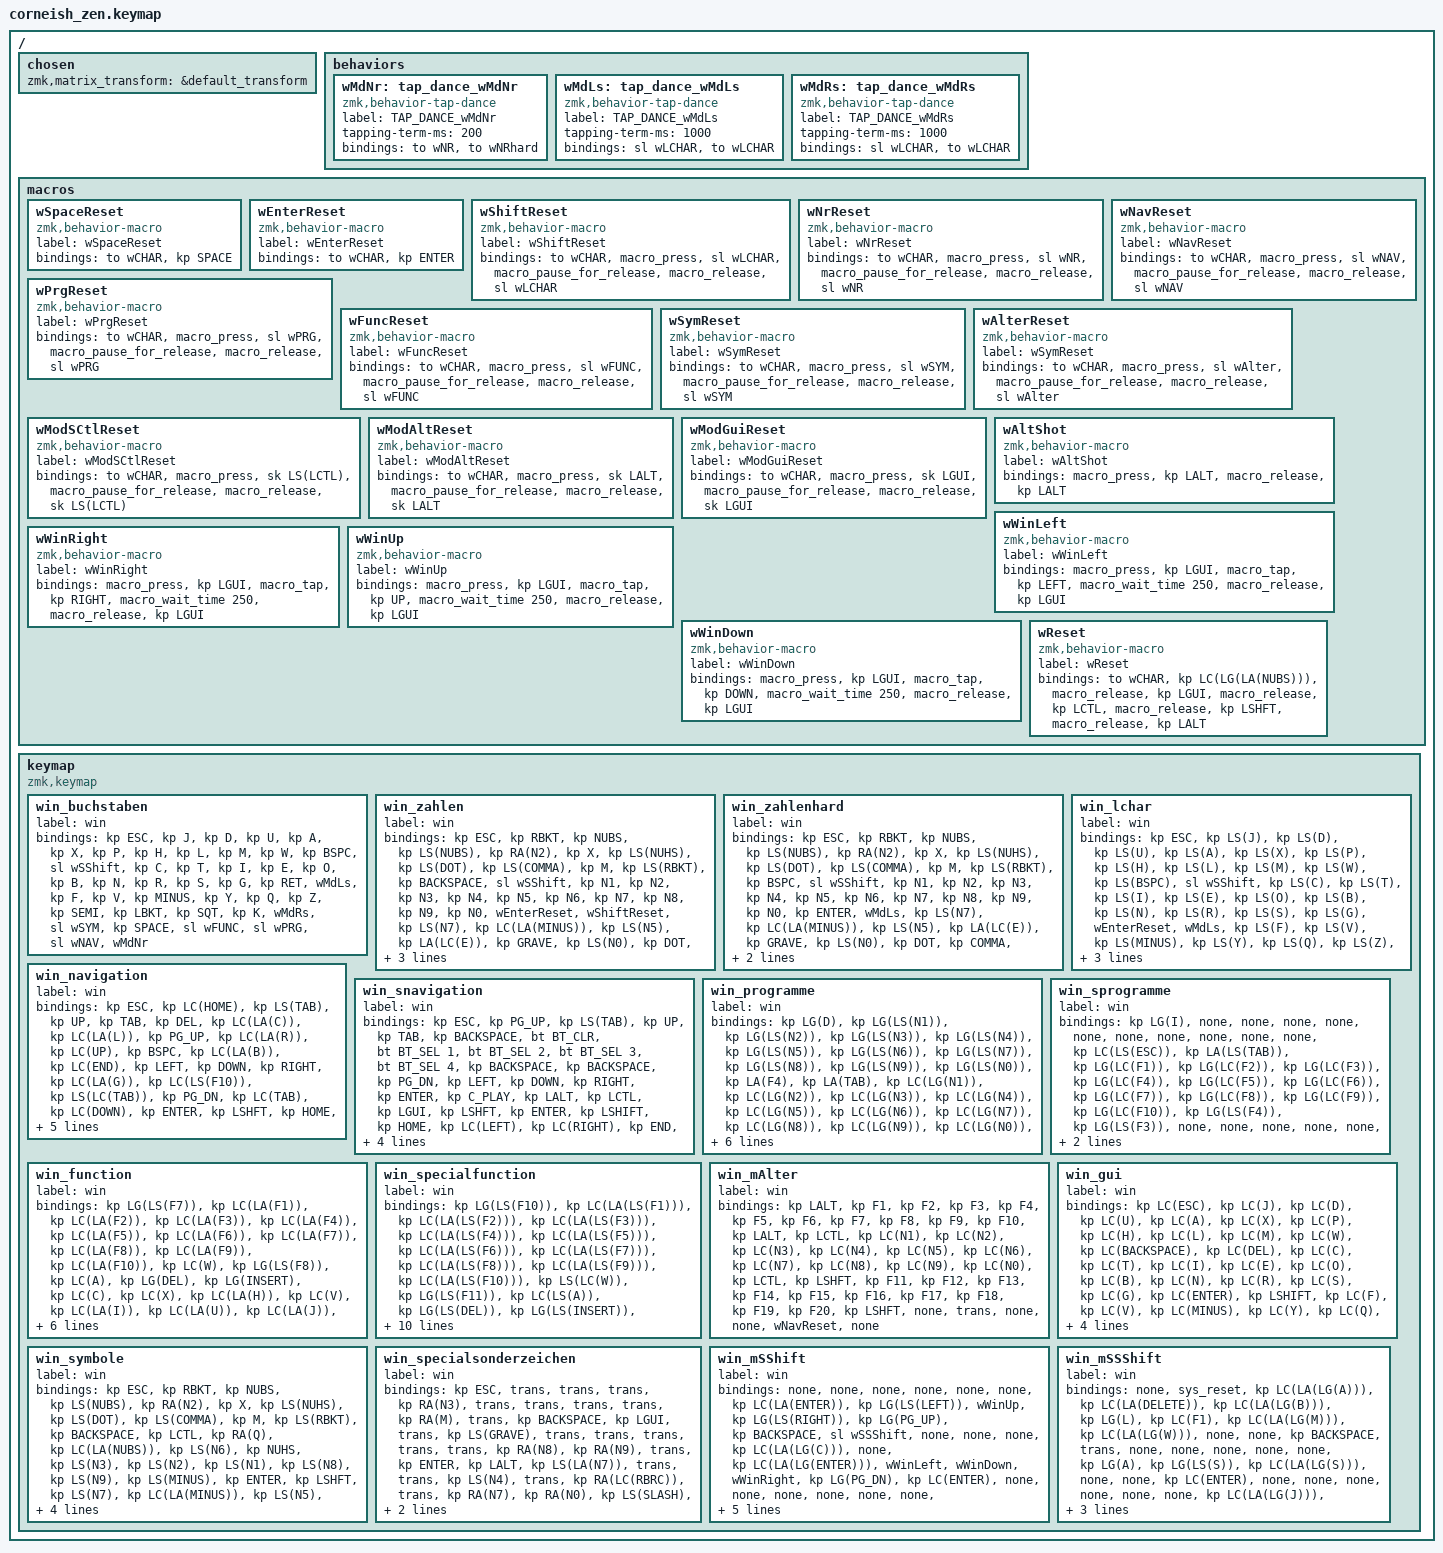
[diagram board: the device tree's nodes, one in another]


#include <behaviors.dtsi>
#include <dt-bindings/zmk/keys.h>
#include <dt-bindings/zmk/bt.h>





// ------- WIN -------------------


#define wCHAR 0
#define wNR 1
#define wNRhard 2
#define wLCHAR 3

#define wNAV 4
#define wSNAV 5

#define wPRG 6
#define wSPRG 7

#define wFUNC 8
#define wSFUNC 9
#define wAlter 10
#define wGUI 11

#define wSYM 12
#define wSSYM 13

#define wSShift 14
#define wSSShift 15



/ {
    chosen {
    	zmk,matrix_transform = &default_transform;
    };
};




/ {

    behaviors 
	{

		// Tap Dance Number
		wMdNr: tap_dance_wMdNr 
		{
            compatible = "zmk,behavior-tap-dance";
            label = "TAP_DANCE_wMdNr";
            #binding-cells = <0>;
            tapping-term-ms = <200>;
            bindings = <&to wNR>, <&to wNRhard>;
        };

		//Tab Dance Shift
		wMdLs: tap_dance_wMdLs 
		{
            compatible = "zmk,behavior-tap-dance";
            label = "TAP_DANCE_wMdLs";
            #binding-cells = <0>;
            tapping-term-ms = <1000>;
            bindings = <&sl wLCHAR>, <&to wLCHAR>;
        };
		wMdRs: tap_dance_wMdRs 
		{
            compatible = "zmk,behavior-tap-dance";
            label = "TAP_DANCE_wMdRs";
            #binding-cells = <0>;
            tapping-term-ms = <1000>;
            bindings = <&sl wLCHAR>, <&to wLCHAR>;
        };

    };

	
	macros 
	{

		//Reset Keys
        wSpaceReset: wSpaceReset 
		{
            label = "wSpaceReset";
            compatible = "zmk,behavior-macro";
            #binding-cells = <0>;
            bindings
                = <&to wCHAR>
                , <&kp SPACE>
                ;
    	};
		wEnterReset: wEnterReset 
		{
            label = "wEnterReset";
            compatible = "zmk,behavior-macro";
            #binding-cells = <0>;
            bindings
                = <&to wCHAR>
                , <&kp ENTER>
                ;
    	};
		wShiftReset: wShiftReset
		{
            label = "wShiftReset";
            compatible = "zmk,behavior-macro";
            #binding-cells = <0>;
            bindings
                = <&to wCHAR>
                , <&macro_press &sl wLCHAR>
    			, <&macro_pause_for_release>
				, <&macro_release &sl wLCHAR>
                ;
    	};



		//Reset Daumen

		wNrReset: wNrReset
		{
            label = "wNrReset";
            compatible = "zmk,behavior-macro";
            #binding-cells = <0>;
            bindings
                = <&to wCHAR>
                , <&macro_press &sl wNR>
    			, <&macro_pause_for_release>
				, <&macro_release &sl wNR>
				;
    	};

				
		wNavReset: wNavReset 
		{
            label = "wNavReset";
            compatible = "zmk,behavior-macro";
            #binding-cells = <0>;
            bindings
                = <&to wCHAR>
                , <&macro_press &sl wNAV>
    			, <&macro_pause_for_release>
				, <&macro_release &sl wNAV>
                ;
    	};

		wPrgReset: wPrgReset 
		{
            label = "wPrgReset";
            compatible = "zmk,behavior-macro";
            #binding-cells = <0>;
            bindings
                = <&to wCHAR>
                , <&macro_press &sl wPRG>
    			, <&macro_pause_for_release>
				, <&macro_release &sl wPRG>
                ;
    	};

		wFuncReset: wFuncReset
		{
            label = "wFuncReset";
            compatible = "zmk,behavior-macro";
            #binding-cells = <0>;
            bindings
                = <&to wCHAR>
                , <&macro_press &sl wFUNC>
    			, <&macro_pause_for_release>
				, <&macro_release &sl wFUNC>
                ;
    	};

		wSymReset: wSymReset
		{
            label = "wSymReset";
            compatible = "zmk,behavior-macro";
            #binding-cells = <0>;
            bindings
                = <&to wCHAR>
                , <&macro_press &sl wSYM>
    			, <&macro_pause_for_release>
				, <&macro_release &sl wSYM>
                ;
    	};



		wAlterReset: wAlterReset
		{
            label = "wSymReset";
            compatible = "zmk,behavior-macro";
            #binding-cells = <0>;
            bindings
                = <&to wCHAR>
                , <&macro_press &sl wAlter>
    			, <&macro_pause_for_release>
				, <&macro_release &sl wAlter>
                ;
    	};


		wModSCtlReset: wModSCtlReset
		{
            label = "wModSCtlReset";
            compatible = "zmk,behavior-macro";
            #binding-cells = <0>;
            bindings
                = <&to wCHAR>
                , <&macro_press &sk LS(LCTL)>
    			, <&macro_pause_for_release>
				, <&macro_release &sk LS(LCTL)>
                ;
    	};


		wModAltReset: wModAltReset
		{
            label = "wModAltReset";
            compatible = "zmk,behavior-macro";
            #binding-cells = <0>;
            bindings
                = <&to wCHAR>
                , <&macro_press &sk LALT>
    			, <&macro_pause_for_release>
				, <&macro_release &sk LALT>
                ;
    	};

		wModGuiReset: wModGuiReset 
		{
            label = "wModGuiReset";
            compatible = "zmk,behavior-macro";
            #binding-cells = <0>;
            bindings
                = <&to wCHAR>
                , <&macro_press &sk LGUI>
    			, <&macro_pause_for_release>
				, <&macro_release &sk LGUI>
                ;
    	};


		// specials

		wAltShot: wAltShot {
            label = "wAltShot";
            compatible = "zmk,behavior-macro";
            #binding-cells = <0>;
            bindings
                = <&macro_press &kp LALT>
				, <&macro_release  &kp LALT>
                ;
    	};


		// Window

		wWinLeft: wWinLeft {
            label = "wWinLeft";
            compatible = "zmk,behavior-macro";
            #binding-cells = <0>;
            bindings
                = <&macro_press &kp LGUI>
				, <&macro_tap &kp LEFT>
				, <&macro_wait_time 250>
				, <&macro_release  &kp LGUI>
                ; 
    	};

		wWinRight: wWinRight {
            label = "wWinRight";
            compatible = "zmk,behavior-macro";
            #binding-cells = <0>;
            bindings
                = <&macro_press &kp LGUI>
				, <&macro_tap &kp RIGHT>
				, <&macro_wait_time 250>
				, <&macro_release  &kp LGUI>
                ; 
    	};

		wWinUp: wWinUp {
            label = "wWinUp";
            compatible = "zmk,behavior-macro";
            #binding-cells = <0>;
            bindings
                = <&macro_press &kp LGUI>
				, <&macro_tap &kp UP>
				, <&macro_wait_time 250>
				, <&macro_release  &kp LGUI>
                ; 
    	};

		wWinDown: wWinDown {
            label = "wWinDown";
            compatible = "zmk,behavior-macro";
            #binding-cells = <0>;
            bindings
                = <&macro_press &kp LGUI>
				, <&macro_tap &kp DOWN>
				, <&macro_wait_time 250>
				, <&macro_release  &kp LGUI>
                ; 
    	};


		// Reset

		wReset: wReset {
            label = "wReset";
            compatible = "zmk,behavior-macro";
            #binding-cells = <0>;
            bindings
				= <&to wCHAR>
				, <&kp LC(LG(LA(NUBS)))>
				, <&macro_release  &kp LGUI>
				, <&macro_release  &kp LCTL>
				, <&macro_release  &kp LSHFT>
				, <&macro_release  &kp LALT>
                ; 
    	};

	};





	keymap
	{	
		compatible = "zmk,keymap";



		// -----------------------------------------------------|
		// Layer 0 - mChar = 	  Buchstaben					|
		// -----------------------------------------------------|
	
		win_buchstaben
		{
			label = "win";

			bindings = <

				// ----------------------------------------

				&kp ESC
				&kp J 
				&kp D	 
				&kp U
				&kp A
				&kp X

				&kp P
				&kp H
				&kp L
				&kp M
				&kp W
				&kp BSPC

				// ----------------------------------------
	
				&sl wSShift
				&kp C
				&kp T
				&kp I
				&kp E
				&kp O

				&kp B
				&kp N
				&kp R
				&kp S
				&kp G
				&kp RET

				// ----------------------------------------
	
				&wMdLs
				&kp F
				&kp V
				&kp MINUS
				&kp Y
				&kp Q

				&kp Z
				&kp SEMI
				&kp LBKT
				&kp SQT
				&kp K
				&wMdRs

				// ----------------------------------------

				&sl wSYM
				&kp SPACE
				&sl wFUNC
				&sl wPRG 
				&sl wNAV
				&wMdNr

				// ----------------------------------------
			>;
		};



		// -----------------------------------------------------|
		// Layer 1 - mNR = 	  Zahlen 							|
		// -----------------------------------------------------|

		win_zahlen
		{
			label = "win";

			bindings = <

				// ----------------------------------------

				&kp ESC	
				&kp RBKT  				// +
				&kp NUBS				// Spitze
				&kp LS(NUBS)			// Spitze
				&kp RA(N2)				// hoch 2
				&kp X
				
				&kp LS(NUHS)			// '
				&kp LS(DOT)				// :
				&kp LS(COMMA)			// ;
				&kp M
				&kp LS(RBKT)			// *				
				&kp BACKSPACE

				// ----------------------------------------

				&sl wSShift
				&kp N1				
				&kp N2				
				&kp N3				
				&kp N4					
				&kp N5		

				&kp N6				
				&kp N7				
				&kp N8			
				&kp N9				
				&kp N0				
				&wEnterReset 

				// ----------------------------------------

				&wShiftReset
				&kp LS(N7)				// /
				&kp LC(LA(MINUS))		// backlslash
				&kp LS(N5)				// %
				&kp LA(LC(E))			// €
				&kp GRAVE				// ^

				&kp LS(N0)				// =
				&kp DOT					// .
				&kp COMMA				// ,
				&kp LS(SLASH)			// _
				&kp SLASH 				// -
				&wShiftReset

				// ----------------------------------------
		
				&wSymReset
				&wSpaceReset 
				&wFuncReset
				&wPrgReset
				&wNavReset
				&none
			>;		
		};



		// -----------------------------------------------------|
		// 2 Layer  - wNRhard = 	  Zahlen Hard Lock				|
		// -----------------------------------------------------|

		win_zahlenhard
		{
			label = "win";

			bindings = <

				// ----------------------------------------

				&kp ESC	
				&kp RBKT  				// +
				&kp NUBS				// Spitze
				&kp LS(NUBS)			// Spitze
				&kp RA(N2)				// hoch 2
				&kp X
				
				&kp LS(NUHS)			// '
				&kp LS(DOT)				// :
				&kp LS(COMMA)			// ;
				&kp M
				&kp LS(RBKT)			// *	
				&kp BSPC

				// ----------------------------------------

				&sl wSShift
				&kp N1				
				&kp N2				
				&kp N3				
				&kp N4					
				&kp N5		

				&kp N6				
				&kp N7				
				&kp N8				
				&kp N9				
				&kp N0				
				&kp ENTER 

				// ----------------------------------------

				&wMdLs
				&kp LS(N7)				// /
				&kp LC(LA(MINUS))		// backlslash
				&kp LS(N5)				// %
				&kp LA(LC(E))			// €
				&kp GRAVE				// ^

				&kp LS(N0)				// =
				&kp DOT					// .
				&kp COMMA				// ,
				&kp LS(SLASH)			// _
				&kp SLASH 				// -
				&wMdRs

				// ----------------------------------------
		
				&sl wSYM
				&kp SPACE
				&sl wFUNC
				&sl wPRG 
				&wNavReset
				&none
			>;		
		};




		// -----------------------------------------------------|
		// 3 Layer  - mLCHAR = 	  Buchstaben Lock				|
		// -----------------------------------------------------|
	
		win_lchar
		{
			label = "win";

			bindings = <

				// ----------------------------------------

				&kp ESC
				&kp LS(J) 
				&kp LS(D)	 
				&kp LS(U)
				&kp LS(A)
				&kp LS(X)

				&kp LS(P)
				&kp LS(H)
				&kp LS(L)
				&kp LS(M)
				&kp LS(W)
				&kp LS(BSPC)

				// ----------------------------------------
	
				&sl wSShift
				&kp LS(C)
				&kp LS(T)
				&kp LS(I)
				&kp LS(E)
				&kp LS(O)
			
				&kp LS(B)
				&kp LS(N)
				&kp LS(R)
				&kp LS(S)
				&kp LS(G)
				&wEnterReset

				// ----------------------------------------

				&wMdLs
				&kp LS(F)
				&kp LS(V)
				&kp LS(MINUS)
				&kp LS(Y)
				&kp LS(Q)

				&kp LS(Z)
				&kp LS(SEMI)
				&kp LS(LBKT)
				&kp LS(SQT)
				&kp LS(K)
				&wMdRs					

				// ----------------------------------------

				&wSymReset
				&wSpaceReset 
				&wFuncReset
				&wPrgReset
				&sl wNAV
				&wMdNr

				// ----------------------------------------		
			>;
		};




		// -----------------------------------------------------|
		// Layer = 4 - wNAV - Navigation						|
		// -----------------------------------------------------|

		win_navigation
		{		
			label = "win";

			bindings = <

				// ----------------------------------------

				&kp ESC
				&kp LC(HOME)				// @Home Sprung
				&kp LS(TAB)
				&kp UP						// @Up
				&kp TAB
				&kp DEL

				&kp LC(LA(C))	
				&kp LC(LA(L))			
				&kp PG_UP
				&kp LC(LA(R))		 	 
				&kp LC(UP)
				&kp BSPC					

				// ----------------------------------------

				&kp LC(LA(B))	
				&kp LC(END)					// @End Sprung
				&kp LEFT 					// @Left
				&kp DOWN					// @Down
				&kp RIGHT 					// @Right
				&kp LC(LA(G))	

				&kp LC(LS(F10))
				&kp LS(LC(TAB))			 	// 
				&kp PG_DN
				&kp LC(TAB)				 	// 
				&kp LC(DOWN)
				&kp ENTER					// -
				
				// ----------------------------------------

				&kp LSHFT
				&kp HOME					// @Home 
				&kp LC(LEFT)				// @Wort Sprung
				&kp LC(RIGHT)				// @Wort Sprung
				&kp END
				&kp LC(LA(LS(C)))	

				&wAltShot
				&kp LS(HOME)					// @Home 
				&kp LS(LC(LEFT))				// @Wort Sprung
				&kp LS(LC(RIGHT))				// @Wort Sprung
				&kp LS(END)
				&kp LSHFT

				// ----------------------------------------

				&sl wSYM
				&kp SPACE				
				&sl wFUNC
				&wReset 
				&sl wSNAV
				&wMdNr

				// ----------------------------------------							
			>;
		};



		// -----------------------------------------------------|
		// Layer = 5 - wSNAV - Navigation						|
		// -----------------------------------------------------|

		win_snavigation
		{		
			label = "win";

			bindings = <

				// ----------------------------------------

				&kp ESC
				&kp PG_UP					//
				&kp LS(TAB)
				&kp UP						// 
				&kp TAB
				&kp BACKSPACE

				&bt BT_CLR
				&bt BT_SEL 1
				&bt BT_SEL 2
				&bt BT_SEL 3
				&bt BT_SEL 4
				&kp BACKSPACE

				// ----------------------------------------
		
				&kp BACKSPACE		
				&kp PG_DN					//
				&kp LEFT
				&kp DOWN
				&kp RIGHT
				&kp ENTER

				&kp C_PLAY					//						//
				&kp LALT					// 
				&kp LCTL					//
				&kp LGUI					//
				&kp LSHFT					// 
				&kp ENTER

				// ----------------------------------------

				&kp LSHIFT						//
				&kp HOME
				&kp LC(LEFT)
				&kp LC(RIGHT)
				&kp END
				&kp RSHIFT						

				&kp C_MUTE					//
				&kp C_PREV					//
				&kp C_VOL_DN						
				&kp C_VOL_UP					
				&kp C_NEXT					// 
				&kp RSHIFT						//	//

				// ----------------------------------------
		
				&sl wSYM
				&kp SPACE				
				&sl wFUNC
				&wReset 
				&wNavReset
				&wMdNr					// 

				// ----------------------------------------							
			>;
		};




		// -----------------------------------------------------|
		// Layer 6 - mPRG =	Programme							|
		// -----------------------------------------------------|


		win_programme
		{
			label = "win";

			bindings = <

				// ----------------------------------------

				&kp LG(D)
				&kp LG(LS(N1))				// 11
				&kp LG(LS(N2))				// 12
				&kp LG(LS(N3))				// 13
				&kp LG(LS(N4))				// 14
				&kp LG(LS(N5))				// 15

				&kp LG(LS(N6))				// 16
				&kp LG(LS(N7))				// 17
				&kp LG(LS(N8))				// 18
				&kp LG(LS(N9))				// 19
				&kp LG(LS(N0))				// 20
				&kp LA(F4)

				// ----------------------------------------

				&kp LA(TAB)
				&kp LC(LG(N1))			//
				&kp LC(LG(N2))			//
				&kp LC(LG(N3))			//
				&kp LC(LG(N4))			//
				&kp LC(LG(N5))			//

				&kp LC(LG(N6))			//
				&kp LC(LG(N7))			//
				&kp LC(LG(N8))			//
				&kp LC(LG(N9))			//
				&kp LC(LG(N0))			//
				&kp LG(TAB)

				// ----------------------------------------

				&kp LG(LS(F1))
				&kp LS(LA(N1))			// 21 			
				&kp LS(LA(N2))			// 22
				&kp LS(LA(N3))			// 23
				&kp LS(LA(N4))			// 24
				&kp LS(LA(N5))			// 25
	
				&kp LS(LA(N6))			// 26
				&kp LS(LA(N7))			// 27
				&kp LS(LA(N8))			// 28
				&kp LS(LA(N9))			// 29
				&kp LS(LA(N0))			// 30
				&kp LG(LS(F2))
		
				// ----------------------------------------

				&none
				&none
				&none
				&sl wSPRG					// deep						
				&wNavReset
				&none

				// ----------------------------------------

			>;
		};
		


		// -----------------------------------------------------|
		// Layer 7 - mSPRG =	Spezial Prgramme				|
		// -----------------------------------------------------|


		win_sprogramme
		{

			label = "win";

			bindings = <

				// ----------------------------------------

				&kp LG(I)				// Hide all
				&none						//
				&none						//
				&none						//
				&none						//
				&none	

				&none						//
				&none						//
				&none						//
				&none						//
				&none	
				&kp LC(LS(ESC))			// Task Manager
		
				// ----------------------------------------

				&kp LA(LS(TAB))				
				&kp LG(LC(F1)) 					
				&kp LG(LC(F2)) 					
				&kp LG(LC(F3))					
				&kp LG(LC(F4)) 					
				&kp LG(LC(F5)) 	

				&kp LG(LC(F6)) 					
				&kp LG(LC(F7)) 					
				&kp LG(LC(F8))					
				&kp LG(LC(F9)) 					
				&kp LG(LC(F10)) 	
				&kp LG(LS(F4))

				// ----------------------------------------

				&kp LG(LS(F3))
				&none						//
				&none						//
				&none						//
				&none						//
				&none	

				&none						//
				&none						//
				&none						//
				&none						//
				&none	
				&kp LG(LS(F4))
		
				// ----------------------------------------

				&none						//
				&none						//
				&none
				&trans						// 
				&wNavReset
				&none						// 

				// ----------------------------------------

			>;
		};




					


		// -----------------------------------------------------|
		// Layer 8 - mFUNC =	Funktionen						|
		// -----------------------------------------------------|

		win_function
		{
			label = "win";

			bindings = <

				// ----------------------------------------
	
				&kp LG(LS(F7))
				&kp LC(LA(F1))	
				&kp LC(LA(F2))	
				&kp LC(LA(F3))	
				&kp LC(LA(F4))	
				&kp LC(LA(F5))	

				&kp LC(LA(F6))	
				&kp LC(LA(F7))	
				&kp LC(LA(F8))	
				&kp LC(LA(F9))	
				&kp LC(LA(F10))	
				&kp LC(W)				
				
				// ----------------------------------------

				&kp LG(LS(F8))
				&kp LC(A)
				&kp LG(DEL)	
				&kp LG(INSERT)	
				&kp LC(C)			
				&kp LC(X)

				&kp LC(LA(H))
				&kp LC(V)
				&kp LC(LA(I))	
				&kp LC(LA(U))	
				&kp LC(LA(J))	
				&kp ENTER

				// ----------------------------------------

				&kp LG(LS(F9))
				&kp LC(S)
				&kp LC(Y)
				&kp LC(Z)
				&kp LC(O)
				&kp LC(DELETE)	

				&kp LC(P)	
				&kp LC(LA(F))	
				&kp LC(KP_PLUS)	
				&kp LC(KP_MINUS)	
				&kp LC(F)	
				&kp LC(T)
				
				// ----------------------------------------

				&wModAltReset
				&sl wGUI					//
				&sl wSFUNC					// deep
				&none
				&wNavReset
				&none						//

				// ----------------------------------------
			>;
		};



		// -----------------------------------------------------|
		// Layer 9 - mSFUNC =	Spezial Funktionen				|
		// -----------------------------------------------------|

		win_specialfunction
		{
			label = "win";

			bindings = <

			// ----------------------------------------
	
				&kp LG(LS(F10))
				&kp LC(LA(LS(F1)))	
				&kp LC(LA(LS(F2)))	
				&kp LC(LA(LS(F3)))	
				&kp LC(LA(LS(F4)))	
				&kp LC(LA(LS(F5)))	

				&kp LC(LA(LS(F6)))	
				&kp LC(LA(LS(F7)))	
				&kp LC(LA(LS(F8)))	
				&kp LC(LA(LS(F9)))
				&kp LC(LA(LS(F10)))
				&kp LS(LC(W))
				
				// ----------------------------------------

				&kp LG(LS(F11))
				&kp LC(LS(A))
				&kp LG(LS(DEL))	
				&kp LG(LS(INSERT))
				&kp LC(LS(C))			
				&kp LC(LS(X))

				&kp LG(V)
				&kp LC(LS(V))
				&kp LC(LS(LA(I)))	
				&kp LC(LS(LA(U)))	
				&kp LC(LS(LA(J)))
				&kp LA(ENTER)	

				// ----------------------------------------

				&kp LG(LS(F12))
				&kp LC(LS(S))
				&kp LC(LS(Y))
				&kp LC(LS(Z))
				&kp LC(LS(O))
				&kp LC(LS(DELETE))

				&kp LC(LS(P))
				&kp LC(LS(LA(F)))	
				&kp LC(LS(KP_PLUS))	
				&kp LC(LS(KP_MINUS))
				&kp LC(LS(F))
				&kp LC(LS(LS(T)))
				
				// ----------------------------------------

				&wModGuiReset
				&wModSCtlReset
				&trans						// 
				&none
				&wNavReset
				&none						//

				// ----------------------------------------       
			>;
		};




		// -----------------------------------------------------|
		// Layer 10 - mAlter =	Alterantive						|
		// -----------------------------------------------------|

		win_mAlter
		{
			label = "win";

			bindings = <

				// ----------------------------------------

				&kp LALT
				&kp F1
				&kp F2
				&kp F3
				&kp F4
				&kp F5

				&kp F6
				&kp F7
				&kp F8
				&kp F9
				&kp F10
				&kp LALT

				// ----------------------------------------
		
				&kp LCTL
				&kp LC(N1)					// 11
				&kp LC(N2)					// 12
				&kp LC(N3)					// 13
				&kp LC(N4)					// 14
				&kp LC(N5)					// 15

				&kp LC(N6)					// 16
				&kp LC(N7)					// 17
				&kp LC(N8)					// 18
				&kp LC(N9)					// 19
				&kp LC(N0)					// 20
				&kp LCTL

				// ----------------------------------------

				&kp LSHFT
				&kp F11
				&kp F12
				&kp F13
				&kp F14
				&kp F15

				&kp F16
				&kp F17
				&kp F18
				&kp F19
				&kp F20
				&kp LSHFT

				// ----------------------------------------
		
				&none						//
				&trans
				&none						// 
				&none						//
				&wNavReset
				&none						// 

				// ----------------------------------------
			>;
		};
		

		// -----------------------------------------------------|
		// Layer 11 - mGUI =	GUI								|
		// -----------------------------------------------------|

		win_gui
		{
			label = "win";

			bindings = <

				// ----------------------------------------

				&kp LC(ESC)					// 
				&kp LC(J)					//
				&kp LC(D)					//
				&kp LC(U)					//
				&kp LC(A)					//
				&kp LC(X)					//

				&kp LC(P)					//
				&kp LC(H)					//
				&kp LC(L) 					//
				&kp LC(M)					//
				&kp LC(W) 					//
				&kp LC(BACKSPACE)			//

				// ----------------------------------------
		
				&kp LC(DEL)					//
				&kp LC(C)					//
				&kp LC(T)					//
				&kp LC(I)					//
				&kp LC(E)					//
				&kp LC(O)					//

				&kp LC(B)					//
				&kp LC(N)					//
				&kp LC(R)					//
				&kp LC(S)					//
				&kp LC(G)					//
				&kp LC(ENTER)				// 

				// ----------------------------------------

				&kp LSHIFT
				&kp LC(F)					//
				&kp LC(V)					//
				&kp LC(MINUS)				//
				&kp LC(Y)					//
				&kp LC(Q)					//

				&kp LC(Z)					//
				&kp LC(SEMICOLON)			//
				&kp LC(LEFT_BRACKET)		//
				&kp LC(SINGLE_QUOTE)		//
				&kp LC(K) 					//
				&kp LSHIFT

				// ----------------------------------------
		
				&none						//
				&kp LC(SPC)
				&none						// 
				&none						//
				&wNavReset
				&none						// 

				// ----------------------------------------
			>;
		};






		// -----------------------------------------------------|
		// Layer 12 - mSYM =	Symoble							|
		// -----------------------------------------------------|

		win_symbole
		{
			label = "win";

			bindings = <

				// ----------------------------------------
				
				&kp ESC
				&kp RBKT  				// +
				&kp NUBS				// Spitze
				&kp LS(NUBS)			// Spitze
				&kp RA(N2)				// hoch 2
				&kp X
				
				&kp LS(NUHS)			// '
				&kp LS(DOT)				// :
				&kp LS(COMMA)			// ;
				&kp M
				&kp LS(RBKT)			// *	
				&kp BACKSPACE			// Backspace

				// ----------------------------------------

				&kp LCTL
				&kp RA(Q)				// @
				&kp LC(LA(NUBS))		// grader strich
				&kp LS(N6)				// &
				&kp NUHS				// #
				&kp LS(N3)				// §

				&kp LS(N2)				// "
				&kp LS(N1)				// !
				&kp LS(N8)				// Runde
				&kp LS(N9)				// Runde
				&kp LS(MINUS)			// ?
				&kp ENTER

				// ----------------------------------------

				&kp LSHFT				//
				&kp LS(N7)				// /
				&kp LC(LA(MINUS))		// backlslash
				&kp LS(N5)				// %
				&kp LA(LC(E))			// €
				&kp GRAVE				// ^

				&kp LS(N0)				// =
				&kp DOT					// .
				&kp COMMA				// ,
				&kp LS(SLASH)			// _
				&kp SLASH 				// -
				&kp LG(DOT)   			// @Sonderzeichen
		
				// ----------------------------------------

				&sl wSSYM				// deep
				&none
				&none					// 
				&none					//
				&wNavReset
				&none					//

				// ----------------------------------------
			>;
		};


		// -----------------------------------------------------|
		// Layer 13 - mSSYM =	Special Symbole					|
		// -----------------------------------------------------|

		win_specialsonderzeichen
		{
			label = "win";

			bindings = <

				// ----------------------------------------

				&kp ESC
				&trans					//
				&trans 					// 
				&trans					//
				&kp RA(N3)				// hoch 3
				&trans					//

				&trans					//
				&trans
				&trans					//
				&kp RA(M)				// 
				&trans					//
				&kp BACKSPACE			// 

				// ----------------------------------------

				&kp LGUI
				&trans					//
				&kp LS(GRAVE)			// Grad
				&trans					//
				&trans					//
				&trans					//

				&trans					//
				&trans					//
				&kp RA(N8)				// Eckige
				&kp RA(N9)				// Eckige
				&trans					//
				&kp ENTER

				// ----------------------------------------

				&kp LALT
				&kp LS(LA(N7))			// 
				&trans
				&trans
				&kp LS(N4) 				// $
				&trans					//

				&kp RA(LC(RBRC))		// ~
				&trans
				&kp RA(N7)				// Geschweift
				&kp RA(N0)				// Geschweift
				&kp LS(SLASH)			// _
				&kp LG(DOT)   			// @Sonderzeichen

				// ----------------------------------------

				&trans					//
				&none
				&none					// 
				&none					//
				&wNavReset
				&none					//

				// ----------------------------------------
			>;
		};	




		// -----------------------------------------------------|
		// Layer 14 - mSideShift =	Side Shift					|
		// -----------------------------------------------------|

		win_mSShift
		{
			label = "win";

			bindings = <

				// ----------------------------------------

				&none
				&none
				&none
				&none
				&none
				&none

				&kp LC(LA(ENTER))	
				&kp LG(LS(LEFT))
				&wWinUp
				&kp LG(LS(RIGHT))
				&kp LG(PG_UP)				
				&kp BACKSPACE			

				// ----------------------------------------
		
				&sl wSSShift
				&none
				&none
				&none
				&kp LC(LA(LG(C)))
				&none

				&kp LC(LA(LG(ENTER)))	
				&wWinLeft
				&wWinDown
				&wWinRight
				&kp LG(PG_DN)			
				&kp LC(ENTER)				// 

				// ----------------------------------------

				&none
				&none
				&none
				&none
				&none
				&none

				&kp LC(LA(LG(F1)))
				&kp LC(LA(LG(F2)))
				&kp LC(LA(LG(F3)))	
				&kp LC(LA(LG(F4)))
				&kp LC(LA(LG(F5)))
				&kp LC(LA(LG(F6)))

				// ----------------------------------------
		
				&wSymReset
				&kp LG(S)
				&wAlterReset				// 
				&wPrgReset					//
				&wNavReset
				&wNrReset

				// ----------------------------------------
			>;
		};



		// -----------------------------------------------------|
		// Layer 15 - mSSideShift =	Side Shift					|
		// -----------------------------------------------------|

		win_mSSShift
		{
			label = "win";

			bindings = <

				// ----------------------------------------

				&none
				&sys_reset
				&kp LC(LA(LG(A)))
				&kp LC(LA(DELETE))
				&kp LC(LA(LG(B)))
				&kp LG(L)

				&kp LC(F1)
				&kp LC(LA(LG(M)))
				&kp LC(LA(LG(W)))
				&none
				&none			
				&kp BACKSPACE			

				// ----------------------------------------
		
				&trans
				&none
				&none
				&none
				&none
				&none

				&kp LG(A)	
				&kp LG(LS(S))
				&kp LC(LA(LG(S)))
				&none
				&none
				&kp LC(ENTER)				// 

				// ----------------------------------------

				&none
				&none
				&none
				&none
				&none
				&none

				&kp LC(LA(LG(J)))
				&kp LC(LA(LG(U)))
				&kp LC(LA(LG(K)))			
				&none	
				&none
				&none

				// ----------------------------------------
		
				&wSymReset
				&kp LG(LA(S))
				&wAlterReset				// 
				&wPrgReset					//
				&wNavReset
				&wNrReset

				// ----------------------------------------
			>;
		};



	};
};

